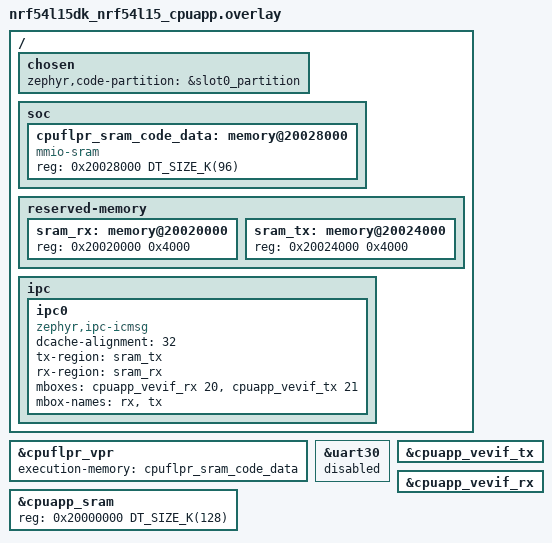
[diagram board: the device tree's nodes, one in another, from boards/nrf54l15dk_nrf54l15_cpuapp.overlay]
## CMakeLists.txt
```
# Copyright (c) 2025 Nordic Semiconductor ASA
# SPDX-License-Identifier: Apache-2.0

cmake_minimum_required(VERSION 3.20.0)

find_package(Zephyr REQUIRED HINTS $ENV{ZEPHYR_BASE})
project(hello_world_with_flpr)

set(FLPR_BIN "${CMAKE_BINARY_DIR}/../coprocessor/zephyr/zephyr.bin")
set(FLPR_HDR "${CMAKE_CURRENT_BINARY_DIR}/include/flpr_firmware.h")
set(BIN2HDR  "${CMAKE_CURRENT_SOURCE_DIR}/scripts/bin_to_header.py")

file(MAKE_DIRECTORY "${CMAKE_CURRENT_BINARY_DIR}/include")

add_custom_command(
    OUTPUT  "${FLPR_HDR}"
    COMMAND "${PYTHON_EXECUTABLE}" -X utf8
                "${BIN2HDR}"
                --input      "${FLPR_BIN}"
                --output     "${FLPR_HDR}"
                --array-name flpr_firmware
    DEPENDS "${FLPR_BIN}" "${BIN2HDR}"
    COMMENT "Generating FLPR firmware header from zephyr.bin"
    VERBATIM
)

add_custom_target(flpr_header_gen DEPENDS "${FLPR_HDR}")
add_dependencies(app flpr_header_gen)
target_include_directories(app PRIVATE "${CMAKE_CURRENT_BINARY_DIR}/include"
				 "${CMAKE_CURRENT_SOURCE_DIR}/ipc")
target_sources(app PRIVATE
    src/main.c
    src/ble_dfu.c
    src/ipc_demo.c
)
```

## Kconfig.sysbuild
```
# Copyright (c) 2025 Nordic Semiconductor ASA
# SPDX-License-Identifier: Apache-2.0

config PARTITION_MANAGER
	default n

config REMOTE_BOARD
	string
	default "$(BOARD)/nrf54lv10a/cpuflpr" if SOC_NRF54LV10A_CPUAPP
	default "$(BOARD)/nrf54l15/cpuflpr" if SOC_NRF54L15_CPUAPP
	default "$(BOARD)/nrf7120/cpuflpr" if SOC_NRF7120_ENGA_CPUAPP

source "${ZEPHYR_BASE}/share/sysbuild/Kconfig"
```

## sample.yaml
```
sample:
  name: Hello World with FLPR + BLE DFU
  description: |
    Multi-image sysbuild sample that runs Hello World on the application
    core and the FLPR coprocessor of the nRF54L15. The FLPR firmware is
    embedded in the application image as a C array and started at runtime;
    firmware updates are performed over Bluetooth.

common:
  sysbuild: true
  tags:
    - ci_samples_nrf_sysbuild_hello_world_flpr
    - bluetooth
    - mcumgr
    - dfu

tests:
  sample.sysbuild.hello_world_with_flpr:
    platform_allow:
      - nrf54l15dk/nrf54l15/cpuapp
    integration_platforms:
      - nrf54l15dk/nrf54l15/cpuapp
    build_only: true
```

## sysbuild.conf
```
SB_CONFIG_BOOTLOADER_MCUBOOT=y
SB_CONFIG_BOOT_SIGNATURE_TYPE_ED25519=y
SB_CONFIG_BOOT_SIGNATURE_TYPE_PURE=y
SB_CONFIG_MCUBOOT_SIGNATURE_USING_KMU=y
SB_CONFIG_MCUBOOT_GENERATE_DEFAULT_KEY_FILE=y
```

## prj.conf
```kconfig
# FLPR is launched from main(), not by the default launcher.
CONFIG_NORDIC_VPR_LAUNCHER=n
CONFIG_RAM_POWER_DOWN_LIBRARY=y
CONFIG_LOG=y

# IPC (icmsg) — same backend as Zephyr samples/subsys/ipc/ipc_service/icmsg
CONFIG_IPC_SERVICE=y
CONFIG_IPC_SERVICE_BACKEND_ICMSG=y
CONFIG_MBOX=y

# Bluetooth - peripheral role used by the SMP transport.
CONFIG_BT=y
CONFIG_BT_PERIPHERAL=y
CONFIG_BT_DEVICE_NAME="DFU Service"

# MCUmgr / SMP server
CONFIG_MCUMGR=y
CONFIG_MCUMGR_TRANSPORT_BT=y
CONFIG_MCUMGR_TRANSPORT_BT_PERM_RW=y
CONFIG_MCUMGR_TRANSPORT_BT_CONN_PARAM_CONTROL=y
CONFIG_MCUMGR_TRANSPORT_BT_REASSEMBLY=y
CONFIG_MCUMGR_TRANSPORT_NETBUF_SIZE=1230
CONFIG_MCUMGR_GRP_OS=y
CONFIG_MCUMGR_GRP_OS_BOOTLOADER_INFO=y
CONFIG_MCUMGR_GRP_OS_MCUMGR_PARAMS=y
CONFIG_MCUMGR_GRP_IMG=y

# Throughput tuning for BLE DFU.
CONFIG_BT_L2CAP_TX_MTU=247
CONFIG_BT_BUF_ACL_TX_SIZE=251
CONFIG_BT_BUF_ACL_RX_SIZE=251
CONFIG_BT_CTLR_DATA_LENGTH_MAX=251

# Storage / image manager dependencies.
CONFIG_CRC=y
CONFIG_FLASH=y
CONFIG_FLASH_MAP=y
CONFIG_STREAM_FLASH=y
CONFIG_IMG_MANAGER=y
CONFIG_NET_BUF=y
CONFIG_ZCBOR=y
```

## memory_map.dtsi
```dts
/*
 * Copyright (c) 2026 Nordic Semiconductor ASA
 *
 * SPDX-License-Identifier: LicenseRef-Nordic-4-Clause
 */

&cpuapp_rram {
	reg = <0x0 DT_SIZE_K(1524)>;

	/* Remove original board defined partition node to allow to allow it to be rewritten */
	/delete-node/ partitions;

	partitions {
		compatible = "fixed-partitions";
		#address-cells = <1>;
		#size-cells = <1>;

		boot_partition: partition@0 {
			label = "mcuboot";
			reg = <0x0 DT_SIZE_K(32)>;
		};

		slot0_partition: partition@8000 {
			label = "image-0";
			reg = <0x8000 DT_SIZE_K(736)>;
		};

		slot1_partition: partition@c0000 {
			label = "image-1";
			reg = <0xc0000 DT_SIZE_K(736)>;
		};

		storage_partition: partition@178000 {
			label = "storage";
			reg = <0x178000 DT_SIZE_K(20)>;
		};
	};
};
```

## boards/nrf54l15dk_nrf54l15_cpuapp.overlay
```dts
#include "../memory_map.dtsi"

/ {
	chosen {
		zephyr,code-partition = &slot0_partition;
	};

	soc {
		cpuflpr_sram_code_data: memory@20028000 {
			compatible = "mmio-sram";
			reg = <0x20028000 DT_SIZE_K(96)>;
			#address-cells = <1>;
			#size-cells = <1>;
			ranges = <0x0 0x20028000 0x18000>;
		};
	};

	reserved-memory {
		#address-cells = <1>;
		#size-cells = <1>;
		ranges;

		sram_rx: memory@20020000 {
			reg = <0x20020000 0x4000>;
		};

		sram_tx: memory@20024000 {
			reg = <0x20024000 0x4000>;
		};
	};

	ipc {
		ipc0: ipc0 {
			compatible = "zephyr,ipc-icmsg";
			dcache-alignment = <32>;
			tx-region = <&sram_tx>;
			rx-region = <&sram_rx>;
			mboxes = <&cpuapp_vevif_rx 20>, <&cpuapp_vevif_tx 21>;
			mbox-names = "rx", "tx";
			status = "okay";
		};
	};
};

&cpuflpr_vpr {
	execution-memory = <&cpuflpr_sram_code_data>;
};

&cpuflpr_vpr {
	status = "okay";
};

&uart30 {
	status = "reserved";
};

&cpuapp_sram {
	reg = <0x20000000 DT_SIZE_K(128)>;
	ranges = <0x0 0x20000000 0x20000>;
};

&cpuapp_vevif_tx {
	status = "okay";
};

&cpuapp_vevif_rx {
	status = "okay";
};
```

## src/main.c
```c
/*
 * Copyright (c) 2024 Nordic Semiconductor ASA
 * SPDX-License-Identifier: Apache-2.0
 */

#include <zephyr/kernel.h>
#include <hal/nrf_vpr.h>
#include "flpr_firmware.h"
#include <hal/nrf_spu.h>
#include <app_version.h>
#include <ram_pwrdn.h>
#include <zephyr/logging/log.h>

#include "ipc_demo.h"

#define LOG_MODULE_NAME app
LOG_MODULE_REGISTER(LOG_MODULE_NAME);

#if DT_NODE_EXISTS(DT_NODELABEL(cpuflpr_sram_code_data))
#define FLPR_SRAM_GLOBAL_ADDR (DT_REG_ADDR(DT_NODELABEL(cpuflpr_sram_code_data)))
#else
#error "DT node cpuflpr_sram_code_data not defined."
#endif

static void flpr_start(void)
{
	power_up_ram(FLPR_SRAM_GLOBAL_ADDR, FLPR_SRAM_GLOBAL_ADDR + FLPR_FIRMWARE_SIZE);

	LOG_INF("Copying %u bytes of FLPR firmware to SRAM @ 0x%08x ...", FLPR_FIRMWARE_SIZE,
		FLPR_SRAM_GLOBAL_ADDR);

	/* Copy the firmware blob into FLPR SRAM. */
	memcpy((uint8_t *)FLPR_SRAM_GLOBAL_ADDR, flpr_firmware, FLPR_FIRMWARE_SIZE);

	nrf_spu_periph_perm_secattr_set(NRF_SPU00, nrf_address_slave_get((uint32_t)NRF_VPR00),
					true);

	nrf_vpr_initpc_set(NRF_VPR00, FLPR_SRAM_GLOBAL_ADDR);
	nrf_vpr_cpurun_set(NRF_VPR00, true);
}

static void flpr_stop(void)
{
	/* Stop VPR */
	nrf_vpr_cpurun_set(NRF_VPR00, false);

	/* Reset the FLPR core */
	nrf_vpr_debugif_dmcontrol_mask_set(
		NRF_VPR00,
		(VPR_DEBUGIF_DMCONTROL_NDMRESET_Active << VPR_DEBUGIF_DMCONTROL_NDMRESET_Pos |
		 VPR_DEBUGIF_DMCONTROL_DMACTIVE_Enabled << VPR_DEBUGIF_DMCONTROL_DMACTIVE_Pos));
	nrf_vpr_debugif_dmcontrol_mask_set(
		NRF_VPR00,
		(VPR_DEBUGIF_DMCONTROL_NDMRESET_Inactive << VPR_DEBUGIF_DMCONTROL_NDMRESET_Pos |
		 VPR_DEBUGIF_DMCONTROL_DMACTIVE_Disabled << VPR_DEBUGIF_DMCONTROL_DMACTIVE_Pos));

	/* Power off RAM to reduce idle current */
	power_down_ram(FLPR_SRAM_GLOBAL_ADDR, (FLPR_SRAM_GLOBAL_ADDR + FLPR_FIRMWARE_SIZE));
}

int main(void)
{
	LOG_INF("Hello world from %s. Version: %s", CONFIG_BOARD_TARGET, APP_VERSION_STRING);
	flpr_start();
	k_msleep(200);
	if (ipc_demo_host_run() != 0) {
		LOG_WRN("IPC demo failed (see logs above)");
	}
	k_msleep(500);
	flpr_stop();
	return 0;
}
```

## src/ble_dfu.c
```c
/*
 * Copyright (c) 2024 Nordic Semiconductor ASA
 * SPDX-License-Identifier: Apache-2.0
 */

#include <zephyr/kernel.h>
#include <zephyr/bluetooth/bluetooth.h>
#include <zephyr/bluetooth/conn.h>
#include <zephyr/bluetooth/gatt.h>
#include <zephyr/mgmt/mcumgr/transport/smp_bt.h>
#include <zephyr/logging/log.h>

LOG_MODULE_REGISTER(ble_dfu, LOG_LEVEL_INF);

static const struct bt_data ad[] = {
	BT_DATA_BYTES(BT_DATA_FLAGS, BT_LE_AD_GENERAL | BT_LE_AD_NO_BREDR),
	BT_DATA(BT_DATA_NAME_COMPLETE, CONFIG_BT_DEVICE_NAME, sizeof(CONFIG_BT_DEVICE_NAME) - 1),
};

static void advertising_start(void)
{
	int err = bt_le_adv_start(BT_LE_ADV_CONN_FAST_2, ad, ARRAY_SIZE(ad), NULL, 0);
	if (err) {
		LOG_ERR("Advertising failed to restart (err %d)", err);
	} else {
		LOG_INF("Advertising as \"%s\"", CONFIG_BT_DEVICE_NAME);
	}
}

static void connected(struct bt_conn *conn, uint8_t err)
{
	if (err) {
		LOG_ERR("Connection failed (err %u)", err);
		return;
	}
	LOG_INF("Connected");
}

static void disconnected(struct bt_conn *conn, uint8_t reason)
{
	LOG_INF("Disconnected (reason %u)", reason);
}

static void recycled(void)
{
	/* Connection object released after disconnnect - restart advertiser */
	advertising_start();
}

BT_CONN_CB_DEFINE(conn_callbacks) = {
	.connected = connected,
	.disconnected = disconnected,
	.recycled = recycled,
};

static int ble_init(void)
{
	int err;

	err = bt_enable(NULL);
	if (err) {
		LOG_ERR("bt_enable failed (err %d)", err);
		return err;
	}
	LOG_INF("Bluetooth initialised");

	advertising_start();

	return 0;
}

/* Run after kernel init, before application main. */
SYS_INIT(ble_init, APPLICATION, CONFIG_APPLICATION_INIT_PRIORITY);
```

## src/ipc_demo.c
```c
/*
 * Copyright (c) 2026 Nordic Semiconductor ASA
 *
 * SPDX-License-Identifier: Apache-2.0
 *
 * Host-side IPC demo modeled on Zephyr samples/subsys/ipc/ipc_service/icmsg.
 */

#include "ipc_demo.h"
#include "ipc_demo_protocol.h"

#include <errno.h>
#include <string.h>

#include <zephyr/device.h>
#include <zephyr/ipc/ipc_service.h>
#include <zephyr/kernel.h>
#include <zephyr/logging/log.h>

LOG_MODULE_REGISTER(ipc_demo_host, LOG_LEVEL_INF);

static K_SEM_DEFINE(ep_bound_sem, 0, 1);
static K_SEM_DEFINE(reply_sem, 0, 1);
static struct ipc_demo_msg last_reply;

static void ep_bound(void *priv)
{
	k_sem_give(&ep_bound_sem);
	LOG_INF("IPC endpoint bound");
}

static void ep_recv(const void *data, size_t len, void *priv)
{
	if (len < sizeof(struct ipc_demo_msg)) {
		return;
	}

	memcpy(&last_reply, data, sizeof(last_reply));

	if (last_reply.magic != IPC_DEMO_MAGIC || last_reply.kind != IPC_DEMO_KIND_REPLY) {
		return;
	}

	k_sem_give(&reply_sem);
}

static void ep_error(const char *message, void *priv)
{
	LOG_ERR("IPC error: %s", message);
}

static struct ipc_ept_cfg ep_cfg = {
	.cb =
		{
			.bound = ep_bound,
			.received = ep_recv,
			.error = ep_error,
		},
};

int ipc_demo_host_run(void)
{
	const struct device *ipc = DEVICE_DT_GET(DT_NODELABEL(ipc0));
	struct ipc_ept ep;
	int ret;

	if (!device_is_ready(ipc)) {
		LOG_ERR("ipc0 device not ready");
		return -ENODEV;
	}

	ret = ipc_service_open_instance(ipc);
	if (ret < 0 && ret != -EALREADY) {
		LOG_ERR("ipc_service_open_instance failed: %d", ret);
		return ret;
	}

	ret = ipc_service_register_endpoint(ipc, &ep, &ep_cfg);
	if (ret < 0) {
		LOG_ERR("ipc_service_register_endpoint failed: %d", ret);
		return ret;
	}

	ret = k_sem_take(&ep_bound_sem, K_SECONDS(5));
	if (ret != 0) {
		LOG_ERR("endpoint bind timeout");
		(void)ipc_service_deregister_endpoint(&ep);
		return ret;
	}

	struct ipc_demo_msg hello = {
		.magic = IPC_DEMO_MAGIC,
		.kind = IPC_DEMO_KIND_HELLO,
		.seq = 1,
	};
	strncpy(hello.payload, "hello", sizeof(hello.payload) - 1);

	for (;;) {
		ret = ipc_service_send(&ep, &hello, sizeof(hello));
		if (ret == (int)sizeof(hello)) {
			break;
		}
		if (ret == -ENOMEM) {
			k_yield();
			continue;
		}
		LOG_ERR("ipc_service_send failed: %d", ret);
		(void)ipc_service_deregister_endpoint(&ep);
		return ret;
	}

	ret = k_sem_take(&reply_sem, K_SECONDS(3));
	if (ret != 0) {
		LOG_ERR("reply timeout");
		(void)ipc_service_deregister_endpoint(&ep);
		return -ETIMEDOUT;
	}

	LOG_INF("IPC reply: seq=%u text=\"%s\"", last_reply.seq, last_reply.payload);

	ret = ipc_service_deregister_endpoint(&ep);
	if (ret < 0) {
		LOG_WRN("ipc_service_deregister_endpoint: %d", ret);
	}

	return 0;
}
```
